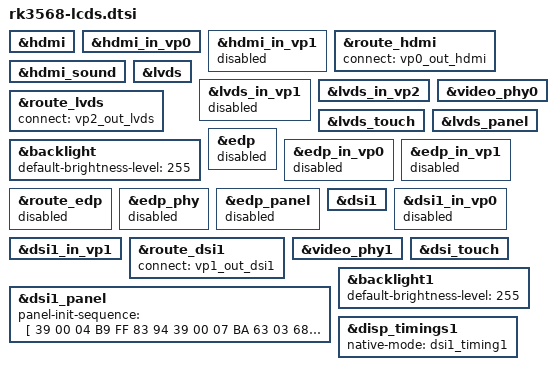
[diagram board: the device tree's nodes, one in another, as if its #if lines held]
/*
 * 通过宏定义来选择对应的LCD, 并使能与该LCD相关的其它外设
 */

/****************** HDMI ***********************/
&hdmi {
	status = "disabled";
};

&hdmi_in_vp0 {
	status = "disabled";
};

&hdmi_in_vp1 {
	status = "disabled";
};

&route_hdmi {
	status = "disabled";
};

&hdmi_sound {
	status = "disabled";
};
/****************** END ************************/


/****************** LVDS ***********************/
&lvds {
	status = "disabled";
};

&lvds_in_vp1 {
	status = "disabled";
};

&lvds_in_vp2 {
	status = "disabled";
};

&route_lvds {
	status = "disabled";
};

&video_phy0 {
	status = "disabled";
};

&lvds_touch {
	status = "disabled";
};

&lvds_panel {
	status = "disabled";
};

&backlight {	//pwm4
	default-brightness-level = <255>;
	status = "disabled";
};
/****************** END ************************/


/****************** EDP  ***********************/
&edp {
	status = "disabled";
};

&edp_in_vp0 {
	status = "disabled";
};

&edp_in_vp1 {
	status = "disabled";
};

&route_edp {
	status = "disabled";
};

&edp_phy {
	status = "disabled";
};

&edp_panel {
	status = "disabled";
};

&backlight {
	status = "disabled";
};
/****************** END ************************/


/****************** MIPI ***********************/
&dsi1 {
	status = "disabled";
};

&dsi1_in_vp0 {
	status = "disabled";
};

&dsi1_in_vp1 {
	status = "disabled";
};

&route_dsi1 {
	status = "disabled";
};

&video_phy1 {
	status = "disabled";
};

&dsi_touch {
	status = "disabled";
};

&dsi1_panel {
	status = "disabled";
};

&backlight1 {	//pwm5
	default-brightness-level = <255>;
	status = "disabled";
};
/****************** END ************************/

/***********************************************/
/************根据宏开启对应的LCD****************/
/***********************************************/
#if defined(ATK_LCD_TYPE_MIPI_720P) || defined(ATK_LCD_TYPE_MIPI_1080P) || defined(ATK_LCD_TYPE_MIPI_10P1_800X1280)
&dsi1 {
	status = "okay";
};

&dsi1_in_vp1 {
	status = "okay";
};

&route_dsi1 {
	connect = <&vp1_out_dsi1>;
	status = "okay";
};

&video_phy1 {
	status = "okay";
};

&dsi_touch {
	status = "okay";
};

&backlight1 {
	status = "okay";
};

&dsi1_panel {
	status = "okay";
};
#endif

#if defined(ATK_LCD_TYPE_MIPI_720P)
&disp_timings1 {	//720p mipi屏时序
	native-mode = <&dsi1_timing1>;
};

&dsi1_panel {
	panel-init-sequence = [ //720p mipi屏参数
		39 00 04 B9 FF 83 94
		39 00 07 BA 63 03 68 6B B2 C0
		//15 00 02 36 01(倒向显示)
		//15 00 02 36 02(正向显示)
		15 00 02 36 01
		39 00 0B B1 48 12 72 09 32 54 71 71 57 47
		39 00 07 B2 00 80 64 0C 0D 2F
		39 00 16 B4 73 74 73 74 73 74 01 0C 86 75 00 3F 73 74 73 74 73 74 01 0C 86
		39 00 03 B6 6E 6E
		39 00 22 D3 00 00 07 07 40 07 0C 00 08 10 08 00 08 54 15 0A 05 0A 02 15 06 05 06 47 44 0A 0A 4B 10 07 07 0C 40
		39 00 2D D5 1C 1C 1D 1D 00 01 02 03 04 05 06 07 08 09 0A 0B 24 25 18 18 26 27 18 18 18 18 18 18 18 18 18 18 18 18 18 18 18 18 20 21 18 18 18 18
		39 00 2D D6 1C 1C 1D 1D 07 06 05 04 03 02 01 00 0B 0A 09 08 21 20 18 18 27 26 18 18 18 18 18 18 18 18 18 18 18 18 18 18 18 18 25 24 18 18 18 18
		39 00 3B E0 00 0A 15 1B 1E 21 24 22 47 56 65 66 6E 82 88 8B 9A 9D 98 A8 B9 5D 5C 61 66 6A 6F 7F 7F 00 0A 15 1B 1E 21 24 22 47 56 65 65 6E 81 87 8B 98 9D 99 A8 BA 5D 5D 62 67 6B 72 7F 7F
		39 00 03 C0 1F 31
		15 00 02 CC 03
		15 00 02 D4 02
		15 00 02 BD 02
		39 00 0D D8 FF FF FF FF FF FF FF FF FF FF FF FF
		15 00 02 BD 00
		15 00 02 BD 01
		15 00 02 B1 00
		15 00 02 BD 00
		39 00 08 BF 40 81 50 00 1A FC 01
		15 00 02 C6 ED
		05 64 01 11
		05 78 01 29
	];
};
#elif defined(ATK_LCD_TYPE_MIPI_1080P)
&disp_timings1 {	//1080p mipi屏时序
	native-mode = <&dsi1_timing0>;
};

&dsi1_panel {
	panel-init-sequence = [  //1080p mipi屏参数
		39 00 04 B9 FF 83 99
		15 00 02 D2 77
		//15 00 02 CC 04(倒向显示)
		//15 00 02 CC 08(正向显示)
		15 00 02 CC 04
		39 00 10 B1 02 04 74 94 01 32 33 11 11 AB 4D 56 73 02 02
		39 00 10 B2 00 80 80 AE 05 07 5A 11 00 00 10 1E 70 03 D4
		39 00 2D B4 00 FF 02 C0 02 C0 00 00 08 00 04 06 00 32 04 0A 08 21 03 01 00 0F B8 8B 02 C0 02 C0 00 00 08 00 04 06 00 32 04 0A 08 01 00 0F B8 01
		39 05 22 D3 00 00 00 00 00 00 06 00 00 10 04 00 04 00 00 00 00 00 00 00 00 00 00 01 00 05 05 07 00 00 00 05 40
		39 05 21 D5 18 18 19 19 18 18 21 20 01 00 07 06 05 04 03 02 18 18 18 18 18 18 2F 2F 30 30 31 31 18 18 18 18
		39 05 21 D6 18 18 19 19 40 40 20 21 02 03 04 05 06 07 00 01 40 40 40 40 40 40 2F 2F 30 30 31 31 40 40 40 40
		39 00 11 D8 A2 AA 02 A0 A2 A8 02 A0 B0 00 00 00 B0 00 00 00
		15 00 02 BD 01
		39 00 11 D8 B0 00 00 00 B0 00 00 00 E2 AA 03 F0 E2 AA 03 F0
		15 00 02 BD 02
		39 00 09 D8 E2 AA 03 F0 E2 AA 03 F0
		15 00 02 BD 00
		39 00 03 B6 8D 8D
		39 05 37 E0 00 0E 19 13 2E 39 48 44 4D 57 5F 66 6C 76 7F 85 8A 95 9A A4 9B AB B0 5C 58 64 77 00 0E 19 13 2E 39 48 44 4D 57 5F 66 6C 76 7F 85 8A 95 9A A4 9B AB B0 5C 58 64 77
		05 c8 01 11
		05 ff 01 29
	];
};
#elif defined(ATK_LCD_TYPE_MIPI_10P1_800X1280)
&disp_timings1 {
	native-mode = <&dsi1_timing2>;
};

&dsi1_panel {
	panel-init-sequence = [
		39 05 04 FF 98 81 03
		05 05 02 01 00
		05 05 02 02 00
		05 05 02 03 53
		05 05 02 04 D3
		05 05 02 05 00
		05 05 02 06 0D
		05 05 02 07 08
		05 05 02 08 00
		05 05 02 09 00
		05 05 02 0a 00
		05 05 02 0b 00
		05 05 02 0c 00
		05 05 02 0d 00
		05 05 02 0e 00
		05 05 02 0f 28
		05 05 02 10 28
		05 05 02 11 00
		05 05 02 12 00
		05 05 02 13 00
		05 05 02 14 00
		05 05 02 15 00
		05 05 02 16 00
		05 05 02 17 00
		05 05 02 18 00
		05 05 02 19 00
		05 05 02 1a 00
		05 05 02 1b 00
		05 05 02 1c 00
		05 05 02 1d 00
		05 05 02 1e 40
		05 05 02 1f 80
		05 05 02 20 06
		05 05 02 21 01
		05 05 02 22 00
		05 05 02 23 00
		05 05 02 24 00
		05 05 02 25 00
		05 05 02 26 00
		05 05 02 27 00
		05 05 02 28 33
		05 05 02 29 33
		05 05 02 2a 00
		05 05 02 2b 00
		05 05 02 2c 00
		05 05 02 2d 00
		05 05 02 2e 00
		05 05 02 2f 00
		05 05 02 30 00
		05 05 02 31 00
		05 05 02 32 00
		05 05 02 33 00
		05 05 02 34 03
		05 05 02 35 00
		05 05 02 36 00
		05 05 02 37 00
		05 05 02 38 96
		05 05 02 39 00
		05 05 02 3a 00
		05 05 02 3b 00
		05 05 02 3c 00
		05 05 02 3d 00
		05 05 02 3e 00
		05 05 02 3f 00
		05 05 02 40 00
		05 05 02 41 00
		05 05 02 42 00
		05 05 02 43 00
		05 05 02 44 00
		05 05 02 50 00
		05 05 02 51 23
		05 05 02 52 45
		05 05 02 53 67
		05 05 02 54 89
		05 05 02 55 AB
		05 05 02 56 01
		05 05 02 57 23
		05 05 02 58 45
		05 05 02 59 67
		05 05 02 5a 89
		05 05 02 5b AB
		05 05 02 5c CD
		05 05 02 5d EF
		05 05 02 5e 00
		05 05 02 5f 08
		05 05 02 60 08
		05 05 02 61 06
		05 05 02 62 06
		05 05 02 63 01
		05 05 02 64 01
		05 05 02 65 00
		05 05 02 66 00
		05 05 02 67 02
		05 05 02 68 15
		05 05 02 69 15
		05 05 02 6a 14
		05 05 02 6b 14
		05 05 02 6c 0D
		05 05 02 6d 0D
		05 05 02 6e 0C
		05 05 02 6f 0C
		05 05 02 70 0F
		05 05 02 71 0F
		05 05 02 72 0E
		05 05 02 73 0E
		05 05 02 74 02
		05 05 02 75 08
		05 05 02 76 08
		05 05 02 77 06
		05 05 02 78 06
		05 05 02 79 01
		05 05 02 7a 01
		05 05 02 7b 00
		05 05 02 7c 00
		05 05 02 7d 02
		05 05 02 7e 15
		05 05 02 7f 15
		05 05 02 80 14
		05 05 02 81 14
		05 05 02 82 0D
		05 05 02 83 0D
		05 05 02 84 0C
		05 05 02 85 0C
		05 05 02 86 0F
		05 05 02 87 0F
		05 05 02 88 0E
		05 05 02 89 0E
		05 05 02 8A 02
		39 05 04 FF 98 81 04
		05 05 02 6E 2B
		05 05 02 6F 37
		05 05 02 3A 24
		05 05 02 8D 1A
		05 05 02 87 BA
		05 05 02 B2 D1
		05 05 02 88 0B
		05 05 02 38 01
		05 05 02 39 00
		05 05 02 B5 02
		05 05 02 31 25
		05 05 02 3B 98
		39 05 04 FF 98 81 01
		05 05 02 22 0A
		05 05 02 31 00
		05 05 02 53 3D
		05 05 02 55 3D
		05 05 02 50 B5
		05 05 02 51 AD
		05 05 02 60 06
		05 05 02 62 20
		05 05 02 A0 00
		05 05 02 A1 21
		05 05 02 A2 35
		05 05 02 A3 19
		05 05 02 A4 1E
		05 05 02 A5 33
		05 05 02 A6 27
		05 05 02 A7 26
		05 05 02 A8 AF
		05 05 02 A9 1B
		05 05 02 AA 27
		05 05 02 AB 8D
		05 05 02 AC 1A
		05 05 02 AD 1B
		05 05 02 AE 50
		05 05 02 AF 26
		05 05 02 B0 2B
		05 05 02 B1 54
		05 05 02 B2 5E
		05 05 02 B3 23
		05 05 02 C0 00
		05 05 02 C1 21
		05 05 02 C2 35
		05 05 02 C3 19
		05 05 02 C4 1E
		05 05 02 C5 33
		05 05 02 C6 27
		05 05 02 C7 26
		05 05 02 C8 AF
		05 05 02 C9 1B
		05 05 02 CA 27
		05 05 02 CB 8D
		05 05 02 CC 1A
		05 05 02 CD 1B
		05 05 02 CE 50
		05 05 02 CF 26
		05 05 02 D0 2B
		05 05 02 D1 54
		05 05 02 D2 5E
		05 05 02 D3 23
		39 05 04 FF 98 81 00
		05 05 02 11 00
		05 78 02 29 00
		05 78 02 35 00
	];
};
#endif


#if defined(ATK_LCD_TYPE_HDMI)
&hdmi {
	status = "okay";
};

&hdmi_in_vp0 {
	status = "okay";
};

&route_hdmi {
	connect = <&vp0_out_hdmi>;
	status = "okay";
};

&hdmi_sound {
	status = "okay";
};
#elif defined(ATK_LCD_TYPE_EDP_VGA)
&edp {
	status = "okay";
};

&edp_in_vp0 {
	status = "okay";
};

&route_edp {
	connect = <&vp0_out_edp>;
	status = "okay";
};

&edp_phy {
	status = "okay";
};

&edp_panel {
	status = "okay";
};

&backlight {
	status = "okay";
};
#endif


#if defined(ATK_LCD_TYPE_LVDS)
&lvds {
	status = "okay";
};

&lvds_in_vp2 {
	status = "okay";
};

&route_lvds {
	connect = <&vp2_out_lvds>;
	status = "okay";
};

&video_phy0 {
	status = "okay";
};

&lvds_touch {
	status = "okay";
};

&lvds_panel {
	status = "okay";
};

&backlight {
	status = "okay";
};
#endif

